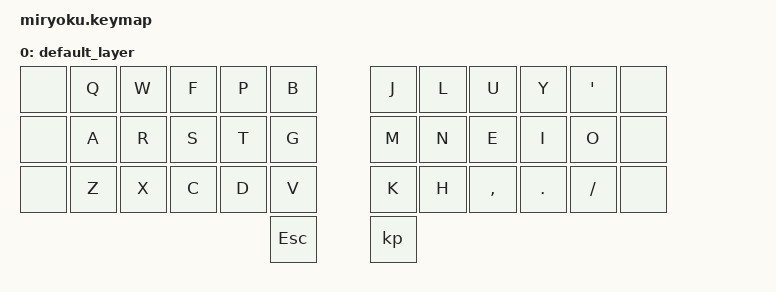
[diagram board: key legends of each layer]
/*
 * Copyright (c) 2020 The ZMK Contributors
 *
 * SPDX-License-Identifier: MIT
 */

#include <behaviors.dtsi>
#include <dt-bindings/zmk/keys.h>
#include <dt-bindings/zmk/bt.h>
#include <dt-bindings/zmk/outputs.h>

/ {
        keymap {
                compatible = "zmk,keymap";

                default_layer {
// ---------------------------------------------------------------
// |     | Q | W |  F  |  P  |  B  | -------- |   J   |   L   |  U  | Y | ' |      |
// |     | A | R |  S  |  T  |  G  | -------- |   M   |   N   |  E  | I | O |      |
// |     | Z | X |  C  |  D  |  V  | -------- |   K   |   H   |  ,  | . | / |      |
//               | Esc | Spc | Tab | -------- | Rtrn  | Bksp  | Del |
                        bindings = <
  &none  &kp Q  &kp W  &kp F  &kp P  &kp B     &kp J  &kp L    &kp U     &kp Y    &kp SQT  &none
  &none  &kp A  &kp R  &kp S  &kp T  &kp G     &kp M  &kp N    &kp E     &kp I    &kp O    &none
  &none  &kp Z  &kp X  &kp C  &kp D  &kp V     &kp K  &kp H  &kp COMMA  &kp DOT  &kp FSLH  &none
  &kp ESC  &kp 
                        >;
                };
};
